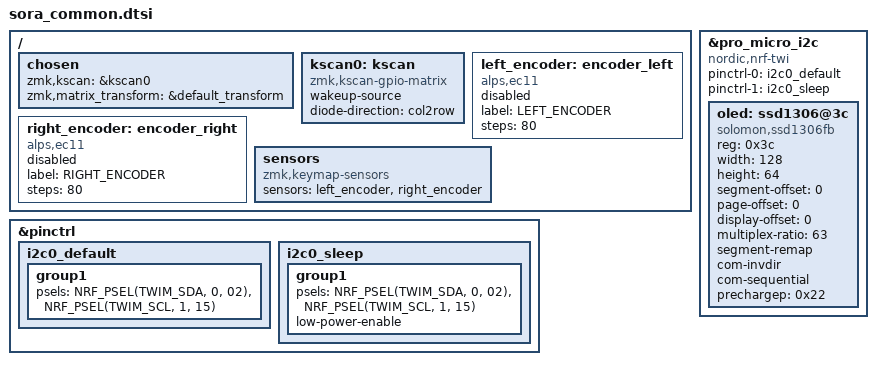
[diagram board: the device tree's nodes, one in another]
#include <dt-bindings/zmk/matrix_transform.h>

/ {
    chosen {
		zmk,kscan = &kscan0;
		zmk,matrix_transform = &default_transform;
	};

    kscan0: kscan {
       compatible = "zmk,kscan-gpio-matrix";
       wakeup-source;
       diode-direction = "col2row";
    };


  left_encoder: encoder_left {
    compatible = "alps,ec11";
    label = "LEFT_ENCODER";
    steps = <80>;
    status = "disabled";  
  };

  right_encoder: encoder_right {
    compatible = "alps,ec11";
    label = "RIGHT_ENCODER";
    steps = <80>;
    status = "disabled";  
  };

    sensors {
      compatible = "zmk,keymap-sensors";
      sensors = <&left_encoder &right_encoder>;
    };
  };

  &pinctrl {
      i2c0_default: i2c0_default {
        group1 {
            psels = <NRF_PSEL(TWIM_SDA, 0, 02)>,
                    <NRF_PSEL(TWIM_SCL, 1, 15)>;
        };
    };

    i2c0_sleep: i2c0_sleep {
        group1 {
            psels = <NRF_PSEL(TWIM_SDA, 0, 02)>,
                    <NRF_PSEL(TWIM_SCL, 1, 15)>;
            low-power-enable;
        };
    };
  };


    &pro_micro_i2c {
        compatible = "nordic,nrf-twi";
        status = "okay";
        pinctrl-0 = <&i2c0_default>;
        pinctrl-1 = <&i2c0_sleep>;
        pinctrl-names = "default", "sleep";
        //clock-frequency = <I2C_BITRATE_FAST>;

        oled: ssd1306@3c {
            compatible = "solomon,ssd1306fb";
            reg = <0x3c>;
            width = <128>;
            height = <64>;
            segment-offset = <0>;
            page-offset = <0>;
            display-offset = <0>;
            multiplex-ratio = <63>;
            segment-remap;
            com-invdir;
            com-sequential;
            prechargep = <0x22>;
        };
    };
